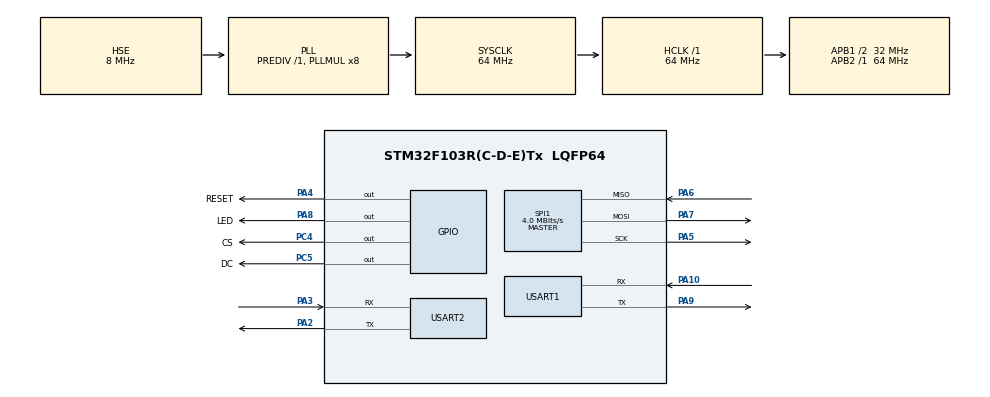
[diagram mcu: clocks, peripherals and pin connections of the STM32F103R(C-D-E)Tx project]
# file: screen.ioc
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Mcu.Family=STM32F1
Mcu.Name=STM32F103R(C-D-E)Tx
Mcu.Package=LQFP64
NVIC.PriorityGroup=NVIC_PRIORITYGROUP_4
NVIC.TIM6_IRQn=true\:0\:0\:false\:false\:true\:true\:true\:true
PA10.Mode=Asynchronous
PA10.Signal=USART1_RX
PA13.Mode=Serial_Wire
PA13.Signal=SYS_JTMS-SWDIO
PA14.Mode=Serial_Wire
PA14.Signal=SYS_JTCK-SWCLK
PA2.Mode=Asynchronous
PA2.Signal=USART2_TX
PA3.Mode=Asynchronous
PA3.Signal=USART2_RX
PA4.GPIO_Label=RESET
PA4.GPIO_Speed=GPIO_SPEED_FREQ_HIGH
PA4.Signal=GPIO_Output
PA5.Mode=Full_Duplex_Master
PA5.Signal=SPI1_SCK
PA6.Mode=Full_Duplex_Master
PA6.Signal=SPI1_MISO
PA7.Mode=Full_Duplex_Master
PA7.Signal=SPI1_MOSI
PA8.GPIO_Label=LED
PA8.GPIO_Speed=GPIO_SPEED_FREQ_HIGH
PA8.Signal=GPIO_Output
PA9.Mode=Asynchronous
PA9.Signal=USART1_TX
PC4.GPIO_Label=CS
PC4.GPIO_Speed=GPIO_SPEED_FREQ_HIGH
PC4.Signal=GPIO_Output
PC5.GPIO_Label=DC
PC5.GPIO_Speed=GPIO_SPEED_FREQ_HIGH
PC5.Signal=GPIO_Output
PD0-OSC_IN.Mode=HSE-External-Oscillator
PD0-OSC_IN.Signal=RCC_OSC_IN
PD1-OSC_OUT.Mode=HSE-External-Oscillator
PD1-OSC_OUT.Signal=RCC_OSC_OUT
ProjectManager.HeapSize=0x200
ProjectManager.StackSize=0x400
ProjectManager.TargetToolchain=MDK-ARM V5.32
RCC.AHBFreq_Value=64000000
RCC.APB1CLKDivider=RCC_HCLK_DIV2
RCC.APB1Freq_Value=32000000
RCC.APB1TimFreq_Value=64000000
RCC.APB2Freq_Value=64000000
RCC.APB2TimFreq_Value=64000000
RCC.HCLKFreq_Value=64000000
RCC.PLLMUL=RCC_PLL_MUL8
RCC.PLLSourceVirtual=RCC_PLLSOURCE_HSE
RCC.SYSCLKFreq_VALUE=64000000
RCC.SYSCLKSource=RCC_SYSCLKSOURCE_PLLCLK
RCC.USBFreq_Value=64000000
SPI1.BaudRatePrescaler=SPI_BAUDRATEPRESCALER_16
SPI1.CLKPhase=SPI_PHASE_2EDGE
SPI1.CLKPolarity=SPI_POLARITY_HIGH
SPI1.CalculateBaudRate=4.0 MBits/s
SPI1.Direction=SPI_DIRECTION_2LINES
SPI1.Mode=SPI_MODE_MASTER
SPI1.VirtualType=VM_MASTER
TIM6.Period=1000-1
TIM6.Prescaler=64-1
USART1.VirtualMode=VM_ASYNC
USART2.VirtualMode=VM_ASYNC
VP_TIM6_VS_ClockSourceINT.Mode=Enable_Timer
board=custom

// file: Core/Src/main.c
/* USER CODE BEGIN Header */
/**
  ******************************************************************************
  * @file           : main.c
  * @brief          : Main program body
  ******************************************************************************
  * @attention
  *
  * Copyright (c) 2023 STMicroelectronics.
  * All rights reserved.
  *
  * This software is licensed under terms that can be found in the LICENSE file
  * in the root directory of this software component.
  * If no LICENSE file comes with this software, it is provided AS-IS.
  *
  ******************************************************************************
  */
/* USER CODE END Header */
#include "main.h"
#include "spi.h"
#include "tim.h"
#include "usart.h"
#include "gpio.h"

/* USER CODE BEGIN Includes */
#include "u8g2.h"
#include "hal_oled.h"
#include "app_timer.h"
#include "tasks.h"
#include "rtthread.h"
/* USER CODE END Includes */

/* USER CODE BEGIN PV */
uint8_t set1 = 1;
uint8_t *set = &set1;
/* USER CODE END PV */

void SystemClock_Config(void);

int main(void)
{

    /* MCU Configuration--------------------------------------------------------*/

    /* Reset of all peripherals, Initializes the Flash interface and the Systick. */
//  HAL_Init();

    /* Configure the system clock */
//  SystemClock_Config();

    /* Initialize all configured peripherals */
    MX_GPIO_Init();
    MX_SPI1_Init();
    MX_TIM6_Init();
    MX_USART1_UART_Init();
    MX_USART2_UART_Init();
    /* USER CODE BEGIN 2 */
    led_task();
    screen_task();
//    HAL_TIM_Base_Start_IT(&htim6);
    /* USER CODE END 2 */

    /* Infinite loop */
    /* USER CODE BEGIN WHILE */
//    uint8_t set =1;
//    while (1)
//    {
//        /* USER CODE END WHILE */

//        /* USER CODE BEGIN 3 */
//        HAL_GPIO_WritePin(LED_GPIO_Port, LED_Pin, set);
//        set ^= 1;
//        rt_thread_mdelay(1000);
//    }

    /* USER CODE END 3 */
}

void SystemClock_Config(void)
{
    RCC_OscInitTypeDef RCC_OscInitStruct = {0};
    RCC_ClkInitTypeDef RCC_ClkInitStruct = {0};

    /** Initializes the RCC Oscillators according to the specified parameters
    * in the RCC_OscInitTypeDef structure.
    */
    RCC_OscInitStruct.OscillatorType = RCC_OSCILLATORTYPE_HSE;
    RCC_OscInitStruct.HSEState = RCC_HSE_ON;
    RCC_OscInitStruct.HSEPredivValue = RCC_HSE_PREDIV_DIV1;
    RCC_OscInitStruct.HSIState = RCC_HSI_ON;
    RCC_OscInitStruct.PLL.PLLState = RCC_PLL_ON;
    RCC_OscInitStruct.PLL.PLLSource = RCC_PLLSOURCE_HSE;
    RCC_OscInitStruct.PLL.PLLMUL = RCC_PLL_MUL8;

    if (HAL_RCC_OscConfig(&RCC_OscInitStruct) != HAL_OK)
    {
        Error_Handler();
    }

    /** Initializes the CPU, AHB and APB buses clocks
    */
    RCC_ClkInitStruct.ClockType = RCC_CLOCKTYPE_HCLK | RCC_CLOCKTYPE_SYSCLK
                                  | RCC_CLOCKTYPE_PCLK1 | RCC_CLOCKTYPE_PCLK2;
    RCC_ClkInitStruct.SYSCLKSource = RCC_SYSCLKSOURCE_PLLCLK;
    RCC_ClkInitStruct.AHBCLKDivider = RCC_SYSCLK_DIV1;
    RCC_ClkInitStruct.APB1CLKDivider = RCC_HCLK_DIV2;
    RCC_ClkInitStruct.APB2CLKDivider = RCC_HCLK_DIV1;

    if (HAL_RCC_ClockConfig(&RCC_ClkInitStruct, FLASH_LATENCY_2) != HAL_OK)
    {
        Error_Handler();
    }
}

void Error_Handler(void)
{
    __disable_irq();
    while (1)
    {
    }
}
